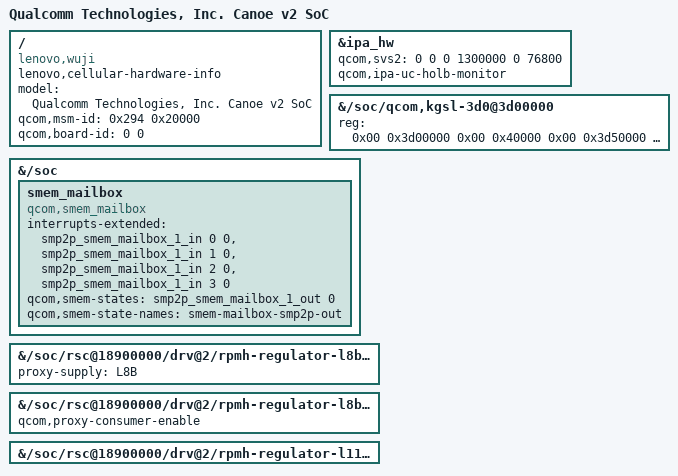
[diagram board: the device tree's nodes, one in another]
// SPDX-License-Identifier: GPL-2.0
// Lenovo TB324ZC: gen6 Canoe v2 base and QTI techpacks.
// Reuse shared Canoe techpack includes; Wuji board data is defined below.
/dts-v1/;
#include "../qcom/canoe-v2.dtsi"
#include "../qcom/canoe-pmic-overlay.dtsi"
#include "canoe-base-techpacks-before-ipa.dtsi"
// Data/canoe-ipa.dts: modem/AP IPA init and SMMU context banks.
#include <dt-bindings/clock/qcom,rpmh.h>
#include "../qcom/data/canoe-ipa.dtsi"
#include "canoe-base-techpacks-after-ipa.dtsi"
#include "canoe-common-base.dtsi"
&ipa_hw {
	/delete-property/ qcom,qmp;
	// Preserve the stock board's SVS2 vote and uC HOLB monitoring.
	qcom,svs2 = <0 0 0 1300000 0 76800>;
	qcom,ipa-uc-holb-monitor;
};

/ {
	lenovo,cellular-hardware-info;
	model = "Qualcomm Technologies, Inc. Canoe v2 SoC";
	compatible = "lenovo,wuji", "qcom,canoe";
	qcom,msm-id = <0x294 0x20000>;
	qcom,board-id = <0 0>;
};

&{/soc/qcom,kgsl-3d0@3d00000} {
	reg = <0x00 0x3d00000 0x00 0x40000 0x00 0x3d50000 0x00 0x10000 0x00 0x3d61000 0x00 0x3000 0x00 0x3d9e000 0x00 0x2000 0x00 0x11100000 0x00 0x80000 0x00 0x10048000 0x00 0x8000 0x00 0x11305000 0x00 0x1000>;
	reg-names = "kgsl_3d0_reg_memory\0rscc\0cx_dbgc\0cx_misc\0qdss_gfx\0qdss_etr\0qdss_tmc";
};

&{/soc} {
	smem_mailbox {
		compatible = "qcom,smem_mailbox";
		interrupts-extended = <&smp2p_smem_mailbox_1_in 0 0>,
			<&smp2p_smem_mailbox_1_in 1 0>,
			<&smp2p_smem_mailbox_1_in 2 0>,
			<&smp2p_smem_mailbox_1_in 3 0>;
		interrupt-names = "smem-mailbox-smp2p-1-in",
			"smem-mailbox-smp2p-2-in",
			"smem-mailbox-smp2p-3-in",
			"smem-mailbox-smp2p-4-in";
		qcom,smem-states = <&smp2p_smem_mailbox_1_out 0>;
		qcom,smem-state-names = "smem-mailbox-smp2p-out";
	};
};

&{/soc/rsc@18900000/drv@2/rpmh-regulator-l8b-e0} {
	proxy-supply = <&L8B>;
};

&{/soc/rsc@18900000/drv@2/rpmh-regulator-l8b-e0/regulator-pmh0101-l8} {
	qcom,proxy-consumer-enable;
};

&{/soc/rsc@18900000/drv@2/rpmh-regulator-l11b-e0/regulator-pmh0101-l11} {
	/delete-property/ qcom,proxy-consumer-enable;
};
